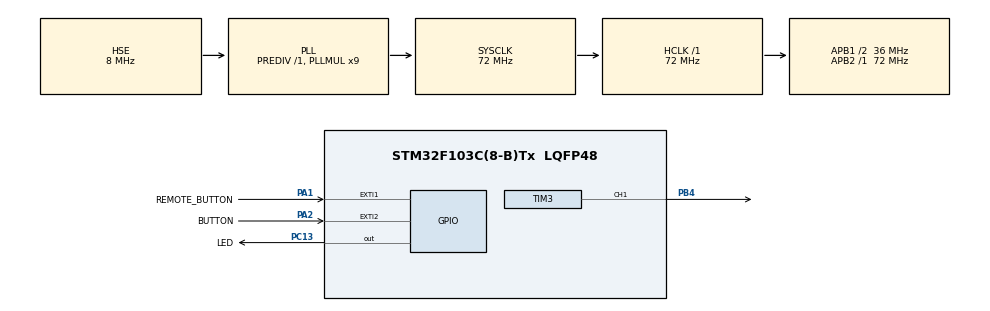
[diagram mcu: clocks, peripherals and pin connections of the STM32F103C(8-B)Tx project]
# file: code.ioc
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Mcu.Family=STM32F1
Mcu.Name=STM32F103C(8-B)Tx
Mcu.Package=LQFP48
NVIC.EXTI1_IRQn=true\:0\:0\:false\:false\:true\:true
NVIC.EXTI2_IRQn=true\:1\:0\:true\:false\:true\:true
NVIC.PriorityGroup=NVIC_PRIORITYGROUP_4
PA1.GPIO_Label=REMOTE_BUTTON
PA1.GPIO_ModeDefaultEXTI=GPIO_MODE_IT_RISING
PA1.GPIO_PuPd=GPIO_PULLDOWN
PA1.Signal=GPXTI1
PA13.Mode=Serial_Wire
PA13.Signal=SYS_JTMS-SWDIO
PA14.Mode=Serial_Wire
PA14.Signal=SYS_JTCK-SWCLK
PA2.GPIO_Label=BUTTON
PA2.GPIO_PuPd=GPIO_PULLDOWN
PA2.Signal=GPXTI2
PB4.Signal=S_TIM3_CH1
PC13-TAMPER-RTC.GPIO_Label=LED
PC13-TAMPER-RTC.Signal=GPIO_Output
PD0-OSC_IN.Mode=HSE-External-Oscillator
PD0-OSC_IN.Signal=RCC_OSC_IN
PD1-OSC_OUT.Mode=HSE-External-Oscillator
PD1-OSC_OUT.Signal=RCC_OSC_OUT
ProjectManager.HeapSize=0x200
ProjectManager.StackSize=0x400
ProjectManager.TargetToolchain=TrueSTUDIO
RCC.AHBFreq_Value=72000000
RCC.APB1CLKDivider=RCC_HCLK_DIV2
RCC.APB1Freq_Value=36000000
RCC.APB1TimFreq_Value=72000000
RCC.APB2Freq_Value=72000000
RCC.APB2TimFreq_Value=72000000
RCC.HCLKFreq_Value=72000000
RCC.PLLMUL=RCC_PLL_MUL9
RCC.PLLSourceVirtual=RCC_PLLSOURCE_HSE
RCC.SYSCLKFreq_VALUE=72000000
RCC.SYSCLKSource=RCC_SYSCLKSOURCE_PLLCLK
RCC.USBFreq_Value=72000000
SH.S_TIM3_CH1.0=TIM3_CH1,PWM Generation1 CH1
TIM3.Channel-PWM\ Generation1\ CH1=TIM_CHANNEL_1
TIM3.Prescaler=72-1
VP_TIM3_VS_ClockSourceINT.Mode=Internal
board=custom

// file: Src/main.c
/* USER CODE BEGIN Header */
/**
  ******************************************************************************
  * @file           : main.c
  * @brief          : Main program body
  ******************************************************************************
  ** This notice applies to any and all portions of this file
  * that are not between comment pairs USER CODE BEGIN and
  * USER CODE END. Other portions of this file, whether
  * inserted by the user or by software development tools
  * are owned by their respective copyright owners.
  *
  * COPYRIGHT(c) 2019 STMicroelectronics
  *
  * Redistribution and use in source and binary forms, with or without modification,
  * are permitted provided that the following conditions are met:
  *   1. Redistributions of source code must retain the above copyright notice,
  *      this list of conditions and the following disclaimer.
  *   2. Redistributions in binary form must reproduce the above copyright notice,
  *      this list of conditions and the following disclaimer in the documentation
  *      and/or other materials provided with the distribution.
  *   3. Neither the name of STMicroelectronics nor the names of its contributors
  *      may be used to endorse or promote products derived from this software
  *      without specific prior written permission.
  *
  * THIS SOFTWARE IS PROVIDED BY THE COPYRIGHT HOLDERS AND CONTRIBUTORS "AS IS"
  * AND ANY EXPRESS OR IMPLIED WARRANTIES, INCLUDING, BUT NOT LIMITED TO, THE
  * IMPLIED WARRANTIES OF MERCHANTABILITY AND FITNESS FOR A PARTICULAR PURPOSE ARE
  * DISCLAIMED. IN NO EVENT SHALL THE COPYRIGHT HOLDER OR CONTRIBUTORS BE LIABLE
  * FOR ANY DIRECT, INDIRECT, INCIDENTAL, SPECIAL, EXEMPLARY, OR CONSEQUENTIAL
  * DAMAGES (INCLUDING, BUT NOT LIMITED TO, PROCUREMENT OF SUBSTITUTE GOODS OR
  * SERVICES; LOSS OF USE, DATA, OR PROFITS; OR BUSINESS INTERRUPTION) HOWEVER
  * CAUSED AND ON ANY THEORY OF LIABILITY, WHETHER IN CONTRACT, STRICT LIABILITY,
  * OR TORT (INCLUDING NEGLIGENCE OR OTHERWISE) ARISING IN ANY WAY OUT OF THE USE
  * OF THIS SOFTWARE, EVEN IF ADVISED OF THE POSSIBILITY OF SUCH DAMAGE.
  *
  ******************************************************************************
  */
/* USER CODE END Header */

#include "main.h"

TIM_HandleTypeDef htim3;

void SystemClock_Config(void);
static void MX_GPIO_Init(void);
static void MX_TIM3_Init(void);

int main(void)
{

  /* MCU Configuration--------------------------------------------------------*/

  /* Reset of all peripherals, Initializes the Flash interface and the Systick. */
  HAL_Init();

  /* Configure the system clock */
  SystemClock_Config();

  /* Initialize all configured peripherals */
  MX_GPIO_Init();
  MX_TIM3_Init();
  /* USER CODE BEGIN 2 */

  if (HAL_SYSTICK_Config(SystemCoreClock / (10000U)) > 0U)
  {
    while(1);
  }

  /* USER CODE END 2 */

  /* Infinite loop */
  while (1)
  {

  }
}

void SystemClock_Config(void)
{
  RCC_OscInitTypeDef RCC_OscInitStruct = {0};
  RCC_ClkInitTypeDef RCC_ClkInitStruct = {0};

  /**Initializes the CPU, AHB and APB busses clocks
  */
  RCC_OscInitStruct.OscillatorType = RCC_OSCILLATORTYPE_HSE;
  RCC_OscInitStruct.HSEState = RCC_HSE_ON;
  RCC_OscInitStruct.HSEPredivValue = RCC_HSE_PREDIV_DIV1;
  RCC_OscInitStruct.HSIState = RCC_HSI_ON;
  RCC_OscInitStruct.PLL.PLLState = RCC_PLL_ON;
  RCC_OscInitStruct.PLL.PLLSource = RCC_PLLSOURCE_HSE;
  RCC_OscInitStruct.PLL.PLLMUL = RCC_PLL_MUL9;
  if (HAL_RCC_OscConfig(&RCC_OscInitStruct) != HAL_OK)
  {
    Error_Handler();
  }
  /**Initializes the CPU, AHB and APB busses clocks
  */
  RCC_ClkInitStruct.ClockType = RCC_CLOCKTYPE_HCLK|RCC_CLOCKTYPE_SYSCLK
                              |RCC_CLOCKTYPE_PCLK1|RCC_CLOCKTYPE_PCLK2;
  RCC_ClkInitStruct.SYSCLKSource = RCC_SYSCLKSOURCE_PLLCLK;
  RCC_ClkInitStruct.AHBCLKDivider = RCC_SYSCLK_DIV1;
  RCC_ClkInitStruct.APB1CLKDivider = RCC_HCLK_DIV2;
  RCC_ClkInitStruct.APB2CLKDivider = RCC_HCLK_DIV1;

  if (HAL_RCC_ClockConfig(&RCC_ClkInitStruct, FLASH_LATENCY_2) != HAL_OK)
  {
    Error_Handler();
  }
}

static void MX_TIM3_Init(void)
{

  TIM_ClockConfigTypeDef sClockSourceConfig = {0};
  TIM_MasterConfigTypeDef sMasterConfig = {0};
  TIM_OC_InitTypeDef sConfigOC = {0};

  htim3.Instance = TIM3;
  htim3.Init.Prescaler = 72-1;
  htim3.Init.CounterMode = TIM_COUNTERMODE_UP;
  htim3.Init.Period = 0;
  htim3.Init.ClockDivision = TIM_CLOCKDIVISION_DIV1;
  htim3.Init.AutoReloadPreload = TIM_AUTORELOAD_PRELOAD_DISABLE;
  if (HAL_TIM_Base_Init(&htim3) != HAL_OK)
  {
    Error_Handler();
  }
  sClockSourceConfig.ClockSource = TIM_CLOCKSOURCE_INTERNAL;
  if (HAL_TIM_ConfigClockSource(&htim3, &sClockSourceConfig) != HAL_OK)
  {
    Error_Handler();
  }
  if (HAL_TIM_PWM_Init(&htim3) != HAL_OK)
  {
    Error_Handler();
  }
  sMasterConfig.MasterOutputTrigger = TIM_TRGO_RESET;
  sMasterConfig.MasterSlaveMode = TIM_MASTERSLAVEMODE_DISABLE;
  if (HAL_TIMEx_MasterConfigSynchronization(&htim3, &sMasterConfig) != HAL_OK)
  {
    Error_Handler();
  }
  sConfigOC.OCMode = TIM_OCMODE_PWM1;
  sConfigOC.Pulse = 0;
  sConfigOC.OCPolarity = TIM_OCPOLARITY_HIGH;
  sConfigOC.OCFastMode = TIM_OCFAST_DISABLE;
  if (HAL_TIM_PWM_ConfigChannel(&htim3, &sConfigOC, TIM_CHANNEL_1) != HAL_OK)
  {
    Error_Handler();
  }
  HAL_TIM_MspPostInit(&htim3);

}

static void MX_GPIO_Init(void)
{
  GPIO_InitTypeDef GPIO_InitStruct = {0};

  /* GPIO Ports Clock Enable */
  __HAL_RCC_GPIOC_CLK_ENABLE();
  __HAL_RCC_GPIOD_CLK_ENABLE();
  __HAL_RCC_GPIOA_CLK_ENABLE();
  __HAL_RCC_GPIOB_CLK_ENABLE();

  /*Configure GPIO pin Output Level */
  HAL_GPIO_WritePin(LED_GPIO_Port, LED_Pin, GPIO_PIN_RESET);

  /*Configure GPIO pin : LED_Pin */
  GPIO_InitStruct.Pin = LED_Pin;
  GPIO_InitStruct.Mode = GPIO_MODE_OUTPUT_PP;
  GPIO_InitStruct.Pull = GPIO_NOPULL;
  GPIO_InitStruct.Speed = GPIO_SPEED_FREQ_LOW;
  HAL_GPIO_Init(LED_GPIO_Port, &GPIO_InitStruct);

  /*Configure GPIO pins : REMOTE_BUTTON_Pin BUTTON_Pin */
  GPIO_InitStruct.Pin = REMOTE_BUTTON_Pin|BUTTON_Pin;
  GPIO_InitStruct.Mode = GPIO_MODE_IT_RISING;
  GPIO_InitStruct.Pull = GPIO_PULLDOWN;
  HAL_GPIO_Init(GPIOA, &GPIO_InitStruct);

  /* EXTI interrupt init*/
  HAL_NVIC_SetPriority(EXTI1_IRQn, 0, 0);
  HAL_NVIC_EnableIRQ(EXTI1_IRQn);

  HAL_NVIC_SetPriority(EXTI2_IRQn, 1, 0);
  HAL_NVIC_EnableIRQ(EXTI2_IRQn);

}

void Error_Handler(void)
{
}

/************************ (C) COPYRIGHT STMicroelectronics *****END OF FILE****/
